# AC7802x register map
Vendor: AutoChips; Series: AC78; File version: 1.0
CPU: CM0PLUS r0p1, little endian, no MPU, no FPU, VTOR, 2 interrupt priority bits
Registers are 32-bit, read-write, reset 0x0 unless marked. A register's access mark holds for its fields unless they carry their own. Offsets are from the block's base; [hi:lo] are bit positions; lines under a group give offsets from that group; {n}, {i} and the like mark numbered series; 'fields as' and 'values as' point back to an identical list.

## ADC0 — Analog to Digital Converter
Base 0x40003000
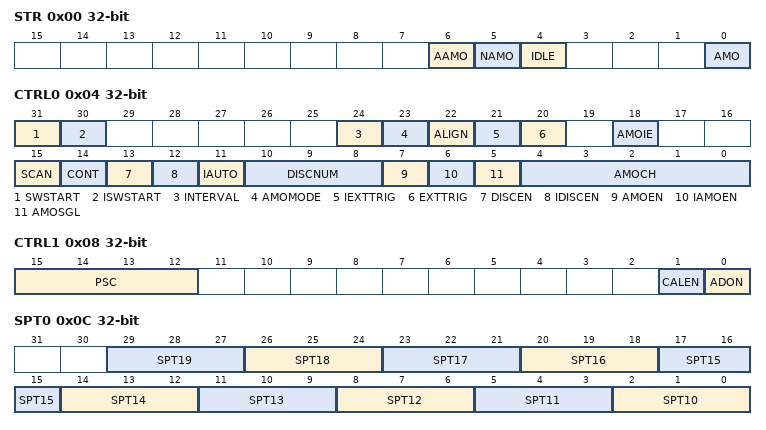
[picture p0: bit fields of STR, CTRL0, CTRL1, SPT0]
0x00 STR — ADC status Register
  [6] AAMO — Analog monitor Abnormal event occurs(Edge mode)
    0=No analog monitor event; 1=Analog monitor abnormal event occurs
  [5] NAMO — Analog monitor normal event occurs(Edge mode)
    0=No analog monitor event; 1=Analog monitor normal event occurs
  [4] IDLE ro — ADC idle status indicate
    0=Busy status; 1=Idle status
  [0] AMO — Analog monitor event occurs(Level mode)
    0=No analog monitor event; 1=Analog monitor event occurs
0x04 CTRL0 — ADC Control Register 0
  [31] SWSTART — Software trigger for regular group
  [30] ISWSTART — Software trigger for Inject group
  [24] INTERVAL — Interval mode
    0=Normal mode; 1=Interval mode
  [23] AMOMODE — Analog monitor type
    0=Level mode; 1=Edge mode
  [22] ALIGN — Data Alignment
    0=Right Alignment; 1=Left Alignment
  [21] IEXTTRIG — Injection group trigger source select
    0=Internal trigger source(software trig); 1=External trigger source
  [20] EXTTRIG — Regular group trigger source select
    values as IEXTTRIG
  [18] AMOIE — AMO interrupt Enable
    0=AMO interrupt Disabled; 1=AMO interrupt Enabled, An interrupt is generated when the AMO bit is set
  [15] SCAN — Scan Mode
    0=Scan mode disabled; 1=Scan mode enabled
  [14] CONT — Continuous conversion
    0=Single conversion mode; 1=Continuous conversion mode
  [13] DISCEN — Discontinous mode on regular group
    0=Regular group Discontinous mode disabled; 1=Regular group Discontinous mode enabled
  [12] IDISCEN — Discontinous mode on Injection group
    0=Injection group Discontinous mode disabled; 1=Injection group Discontinous mode enabled
  [11] IAUTO — Injection Group Automatic Conversion
    0=Injection group automatic conversion disabled; 1=Injection group automatic conversion enabled
  [10:8] DISCNUM — Discontinuous conversion length of Regular Group
  [7] AMOEN — Regular Group Analog Monitor Detect function Enable
  [6] IAMOEN — Injection Group Analog Monitor Detect function Enable
  [5] AMOSGL — Analog monitor detecting channel
    0=AMO used in All channels; 1=AMO function used in single channel defined in AMOCH register
  [4:0] AMOCH — Analog monitor detecting channel
0x08 CTRL1 — ADC Control Register 1
  [15:12] PSC — Input clock prescaler
    {v}=Divide by {v+1} (v=0..15)
  [1] CALEN — Calibration calculation
    0=Disable Calibration; 1=Enable Calibration
  [0] ADON — ADC converter ON/OFF
    0=ADC converter power off; 1=ADC converter power on
0x0C SPT0 — ADC Sample time setting register 0
  [all] fields
    0=9 ADCCLK; 1=7 ADCCLK; 2=17 ADCCLK; 3=33 ADCCLK; 4=64 ADCCLK; 5=140 ADCCLK; 6=215 ADCCLK; 7=5 ADCCLK
  [3n-28:3n-30] SPT{n} (n=10..19) — Sample time for Channel {n}
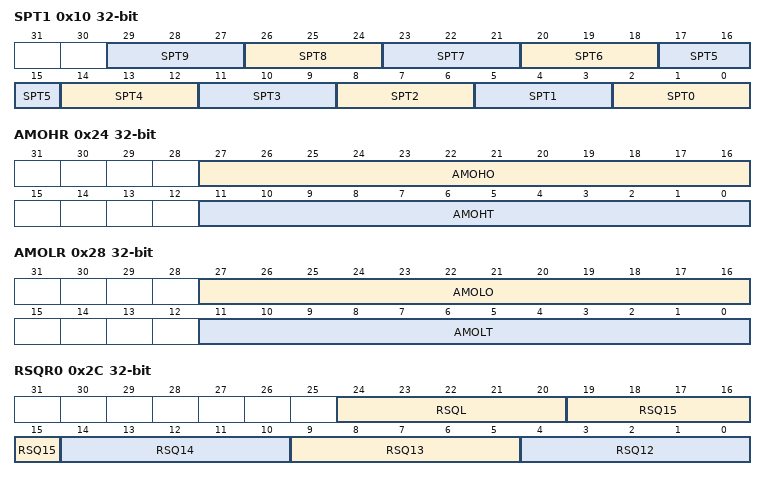
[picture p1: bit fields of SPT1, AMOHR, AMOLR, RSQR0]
0x10 SPT1 — ADC Sample time setting register 1
  [all] fields
    values as the fields of SPT0
  [3n+2:3n] SPT{n} (n=0..9) — Sample time for Channel {n}
{0x14+4i} IOFR{i} (i=0..3) — ADC Injection Group Offset Register(n)
  [11:0] IOFR — Injection group offset Value
0x24 AMOHR — AMO High threshold and offset register
  [27:16] AMOHO — High offset value
  [11:0] AMOHT — AMO High threshold value
0x28 AMOLR — AMO Low threshold and offset register
  [27:16] AMOLO — Low offset value
  [11:0] AMOLT — AMO Low threshold value
0x2C RSQR0 — ADC regular group sequence configure register 0
  [24:20] RSQL — Length of Regular Group
  [5n-56:5n-60] RSQ{n} (n=12..15) — Channel selection for regular sequence {n}
    {v}=Exernal channel {v} is selected as input (v=0..18); 19=Internal channel is selected as input; 31=No channel is selected as input
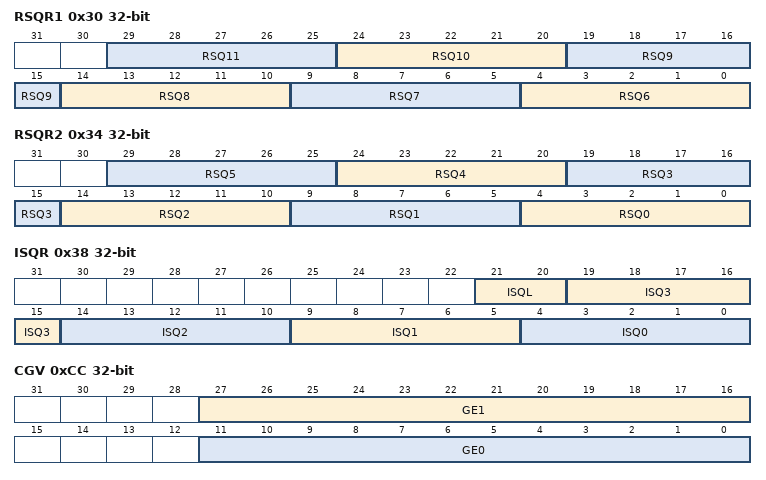
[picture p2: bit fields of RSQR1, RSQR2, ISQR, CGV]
0x30 RSQR1 — ADC regular group sequence configure register 1
  [all] fields
    values as RSQR0.RSQ12
  [5n-26:5n-30] RSQ{n} (n=6..11) — Channel selection for regular sequence {n}
0x34 RSQR2 — ADC regular group sequence configure register 2
  [all] fields
    values as RSQR0.RSQ12
  [5n+4:5n] RSQ{n} (n=0..5) — Channel selection for regular sequence {n}
0x38 ISQR — ADC Injection group sequence configure register
  [21:20] ISQL — Length of the injection group
  [5n+4:5n] ISQ{n} (n=0..3) — Channel selection for injection sequence {n}
    values as RSQR0.RSQ12
{0x3C+4i} IDR{i} (i=0..3) ro — ADC Injection Group data Register(n)
  [15:0] IDR — Injection group data value
{0x4C+4i} RDR{i} (i=0..20) ro — ADC Regular Group data Register(n)
  [15:0] RDR — Regular group data value
0xCC CGV — ADC Calibration Gain Error Register
  [27:16] GE1 — Gain error value for channel > 18
  [11:0] GE0 — Gain error value for channel 0 ~ 18
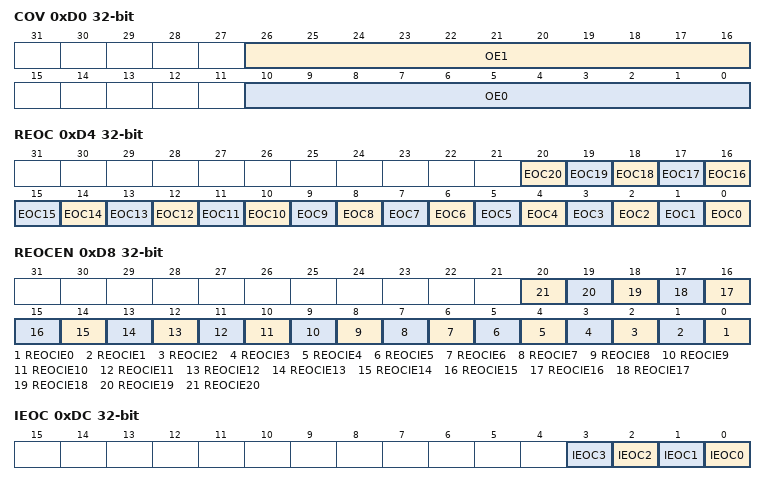
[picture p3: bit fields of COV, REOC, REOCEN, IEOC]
0xD0 COV — ADC Calibration Offset Error Register
  [26:16] OE1 — Offset error value for channel > 18
  [10:0] OE0 — Offset error value for channel 0~18
0xD4 REOC — ADC Regular Group EOC interrupt Status Register
  [n] EOC{n} (n=0..20) — Regular sequence {n} EOC flag
0xD8 REOCEN — ADC Regular Group EOC interrupt Enable Register
  [n] REOCIE{n} (n=0..20) — Regular sequence {n} EOC Interrupt Enable
    0=regular sequence {n} conversion completed not trig interrupt; 1=regular sequence {n} conversion completed trig interrupt
0xDC IEOC — ADC Regular Group EOC interrupt Status Register
  [n] IEOC{n} (n=0..3) — Inject sequence {n} EOC flag
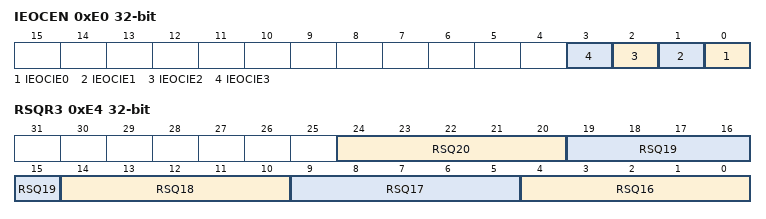
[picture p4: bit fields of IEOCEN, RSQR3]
0xE0 IEOCEN — ADC Regular Group EOC interrupt Enable Register
  [n] IEOCIE{n} (n=0..3) — Inject sequence {n} EOC Interrupt Enable
    0=inject sequence {n} conversion completed not trig interrupt; 1=inject sequence {n} conversion completed trig interrupt
0xE4 RSQR3 — ADC regular group sequence configure register 3
  [all] fields
    values as RSQR0.RSQ12
  [5n-76:5n-80] RSQ{n} (n=16..20) — Channel selection for regular sequence {n}
